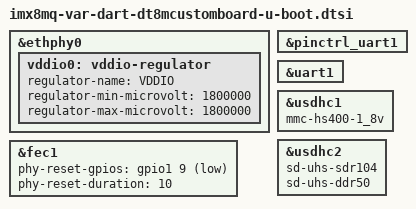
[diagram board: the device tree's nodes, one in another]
// SPDX-License-Identifier: (GPL-2.0 OR MIT)
/*
 * Copyright 2018-2024 Variscite Ltd.
 */

#include "imx8mq-u-boot.dtsi"

&ethphy0 {
	vddio0: vddio-regulator {
		regulator-name = "VDDIO";
		regulator-min-microvolt = <1800000>;
		regulator-max-microvolt = <1800000>;
	};
};

&fec1 {
	phy-reset-gpios = <&gpio1 9 GPIO_ACTIVE_LOW>;
	phy-reset-duration = <10>;
};

&pinctrl_uart1 {
	u-boot,dm-spl;
};

&uart1 {
	u-boot,dm-spl;
};

&usdhc1 {
	mmc-hs400-1_8v;
};

&usdhc2 {
	sd-uhs-sdr104;
	sd-uhs-ddr50;
};
